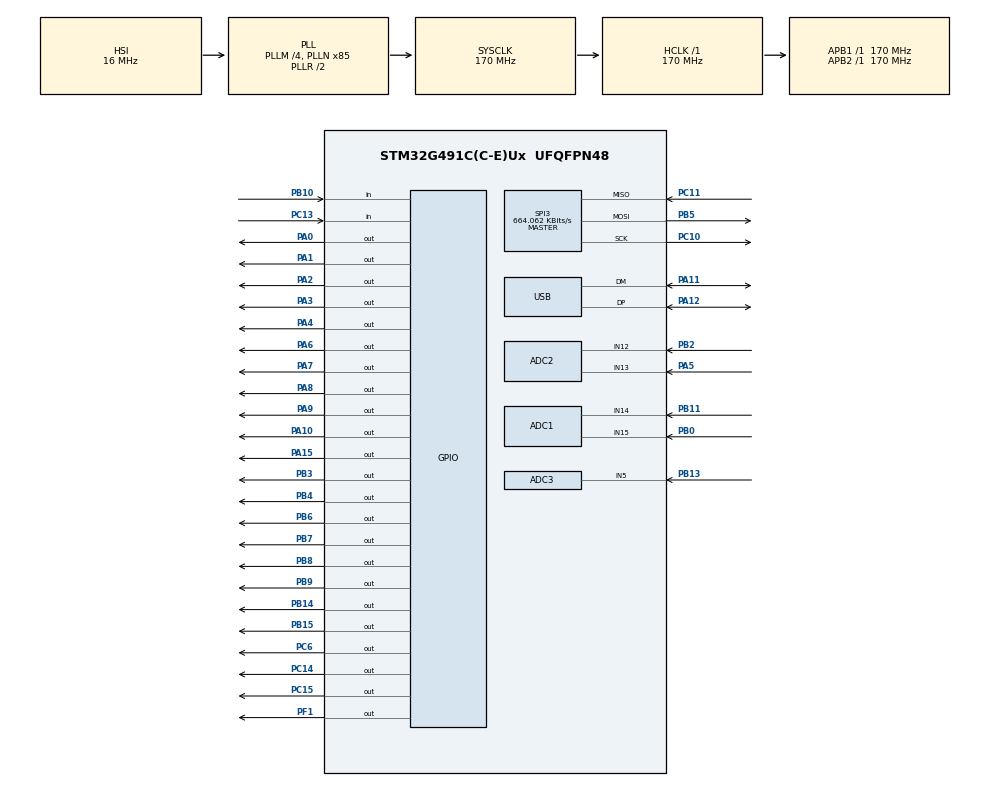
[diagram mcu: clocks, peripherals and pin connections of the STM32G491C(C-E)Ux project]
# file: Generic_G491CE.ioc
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ADC1.Channel-0\#ChannelRegularConversion=ADC_CHANNEL_14
ADC1.NbrOfConversionFlag=1
ADC1.OffsetNumber-0\#ChannelRegularConversion=ADC_OFFSET_NONE
ADC1.Rank-0\#ChannelRegularConversion=1
ADC1.SamplingTime-0\#ChannelRegularConversion=ADC_SAMPLETIME_2CYCLES_5
ADC1.SingleDiff-0\#ChannelRegularConversion=ADC_DIFFERENTIAL_ENDED
ADC1.master=1
ADC2.Channel-0\#ChannelRegularConversion=ADC_CHANNEL_12
ADC2.NbrOfConversionFlag=1
ADC2.OffsetNumber-0\#ChannelRegularConversion=ADC_OFFSET_NONE
ADC2.Rank-0\#ChannelRegularConversion=1
ADC2.SamplingTime-0\#ChannelRegularConversion=ADC_SAMPLETIME_2CYCLES_5
ADC2.SingleDiff-0\#ChannelRegularConversion=ADC_DIFFERENTIAL_ENDED
ADC3.Channel-0\#ChannelRegularConversion=ADC_CHANNEL_5
ADC3.NbrOfConversionFlag=1
ADC3.OffsetNumber-0\#ChannelRegularConversion=ADC_OFFSET_NONE
ADC3.Rank-0\#ChannelRegularConversion=1
ADC3.SamplingTime-0\#ChannelRegularConversion=ADC_SAMPLETIME_2CYCLES_5
ADC3.master=1
FREERTOS.Tasks01=BlinkTask1,24,128,BlinkTask1Function,Default,NULL,Dynamic,NULL,NULL;BlinkTask2,8,128,BlinkTask2Function,Default,NULL,Dynamic,NULL,NULL
FREERTOS.configUSE_NEWLIB_REENTRANT=1
Mcu.Family=STM32G4
Mcu.Name=STM32G491C(C-E)Ux
Mcu.Package=UFQFPN48
NVIC.PriorityGroup=NVIC_PRIORITYGROUP_4
NVIC.TIM6_DAC_IRQn=true\:15\:0\:false\:false\:true\:false\:false\:true\:true
NVIC.TimeBase=TIM6_DAC_IRQn
NVIC.TimeBaseIP=TIM6
NVIC.USB_LP_IRQn=true\:5\:0\:false\:false\:true\:true\:false\:true\:true
PA0.Signal=GPIO_Output
PA1.Signal=GPIO_Output
PA10.Signal=GPIO_Output
PA11.Mode=Device
PA11.Signal=USB_DM
PA12.Mode=Device
PA12.Signal=USB_DP
PA13.Mode=Serial_Wire
PA13.Signal=SYS_JTMS-SWDIO
PA14.Mode=Serial_Wire
PA14.Signal=SYS_JTCK-SWCLK
PA15.Signal=GPIO_Output
PA2.Signal=GPIO_Output
PA3.Signal=GPIO_Output
PA4.Signal=GPIO_Output
PA5.Mode=IN12-Differential
PA5.Signal=ADC2_IN13
PA6.Signal=GPIO_Output
PA7.Signal=GPIO_Output
PA8.Signal=GPIO_Output
PA9.Signal=GPIO_Output
PB0.Mode=IN14-Differential
PB0.Signal=ADC1_IN15
PB1.Signal=ADC1_IN12
PB10.Signal=GPIO_Input
PB11.Mode=IN14-Differential
PB11.Signal=ADC1_IN14
PB12.Signal=ADC1_IN11
PB13.Mode=IN5-Single-Ended
PB13.Signal=ADC3_IN5
PB14.Signal=GPIO_Output
PB15.Signal=GPIO_Output
PB2.Mode=IN12-Differential
PB2.Signal=ADC2_IN12
PB3.Signal=GPIO_Output
PB4.Signal=GPIO_Output
PB5.Mode=Full_Duplex_Master
PB5.Signal=SPI3_MOSI
PB6.Signal=GPIO_Output
PB7.Signal=GPIO_Output
PB8-BOOT0.Signal=GPIO_Output
PB9.Signal=GPIO_Output
PC10.Mode=Full_Duplex_Master
PC10.Signal=SPI3_SCK
PC11.Mode=Full_Duplex_Master
PC11.Signal=SPI3_MISO
PC13.Signal=GPIO_Input
PC14-OSC32_IN.Signal=GPIO_Output
PC15-OSC32_OUT.Signal=GPIO_Output
PC4.Signal=I2C2_SCL
PC6.Signal=GPIO_Output
PF0-OSC_IN.Signal=I2C2_SDA
PF1-OSC_OUT.Signal=GPIO_Output
ProjectManager.HeapSize=0x200
ProjectManager.StackSize=0x400
ProjectManager.TargetToolchain=STM32CubeIDE
RCC.ADC12Freq_Value=170000000
RCC.ADC345Freq_Value=170000000
RCC.AHBFreq_Value=170000000
RCC.APB1Freq_Value=170000000
RCC.APB1TimFreq_Value=170000000
RCC.APB2Freq_Value=170000000
RCC.APB2TimFreq_Value=170000000
RCC.CortexFreq_Value=170000000
RCC.EXTERNAL_CLOCK_VALUE=12288000
RCC.HCLKFreq_Value=170000000
RCC.HSE_VALUE=8000000
RCC.HSI48_VALUE=48000000
RCC.HSI_VALUE=16000000
RCC.LSE_VALUE=32768
RCC.PLLM=RCC_PLLM_DIV4
RCC.PLLN=85
RCC.SYSCLKFreq_VALUE=170000000
RCC.SYSCLKSource=RCC_SYSCLKSOURCE_PLLCLK
RCC.USBFreq_Value=48000000
RCC.VCOOutputFreq_Value=340000000
SPI3.BaudRatePrescaler=SPI_BAUDRATEPRESCALER_256
SPI3.CalculateBaudRate=664.062 KBits/s
SPI3.Direction=SPI_DIRECTION_2LINES
SPI3.Mode=SPI_MODE_MASTER
SPI3.VirtualType=VM_MASTER
USB_DEVICE.CLASS_NAME_FS=DFU
USB_DEVICE.VirtualMode=Dfu
USB_DEVICE.VirtualModeFS=Dfu_FS
VP_CORDIC_VS_CORDIC.Mode=CORDIC_Activate
VP_FMAC_VS_FMAC.Mode=FMAC_Activate
VP_FREERTOS_VS_CMSIS_V2.Mode=CMSIS_V2
VP_RCC_VS_USB.Mode=USB_FS
VP_SYS_VS_DBSignals.Mode=DisableDeadBatterySignals
VP_SYS_VS_tim6.Mode=TIM6
VP_USB_DEVICE_VS_USB_DEVICE_DFU_FS.Mode=DFU_FS
board=custom

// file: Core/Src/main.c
/* USER CODE BEGIN Header */
/**
  ******************************************************************************
  * @file           : main.c
  * @brief          : Main program body
  ******************************************************************************
  * @attention
  *
  * Copyright (c) 2022 STMicroelectronics.
  * All rights reserved.
  *
  * This software is licensed under terms that can be found in the LICENSE file
  * in the root directory of this software component.
  * If no LICENSE file comes with this software, it is provided AS-IS.
  *
  ******************************************************************************
  */
/* USER CODE END Header */
#include "main.h"
#include "cmsis_os.h"
#include "usb_device.h"

ADC_HandleTypeDef hadc1;
ADC_HandleTypeDef hadc2;
ADC_HandleTypeDef hadc3;

CORDIC_HandleTypeDef hcordic;

FMAC_HandleTypeDef hfmac;

SPI_HandleTypeDef hspi3;

/* Definitions for BlinkTask1 */
osThreadId_t BlinkTask1Handle;
const osThreadAttr_t BlinkTask1_attributes = {
  .name = "BlinkTask1",
  .priority = (osPriority_t) osPriorityNormal,
  .stack_size = 128 * 4
};
/* Definitions for BlinkTask2 */
osThreadId_t BlinkTask2Handle;
const osThreadAttr_t BlinkTask2_attributes = {
  .name = "BlinkTask2",
  .priority = (osPriority_t) osPriorityLow,
  .stack_size = 128 * 4
};

void SystemClock_Config(void);
static void MX_GPIO_Init(void);
static void MX_ADC1_Init(void);
static void MX_ADC2_Init(void);
static void MX_ADC3_Init(void);
static void MX_SPI3_Init(void);
static void MX_CORDIC_Init(void);
static void MX_FMAC_Init(void);
void BlinkTask1Function(void *argument);
void BlinkTask2Function(void *argument);

/* USER CODE BEGIN 0 */
//void jump_to_bootloader( void )
//{
//	__enable_irq();
//	HAL_RCC_DeInit();
//	HAL_DeInit();
//	SysTick->CTRL = SysTick->LOAD = SysTick->VAL = 0;
//	__HAL_SYSCFG_REMAPMEMORY_SYSTEMFLASH();
//
//	const uint32_t p = (*((uint32_t *) 0x1FFF0000));
//	__set_MSP( p );
//
//	void (*SysMemBootJump)(void);
//	SysMemBootJump = (void (*)(void)) (*((uint32_t *) 0x1FFF0004));
//	SysMemBootJump();
//
//	while( 1 ) {}
//}

/* USER CODE END 0 */

int main(void)
{
  /* USER CODE BEGIN 1 */

//	// Our STM32 F072 has:
//	// 16k SRAM in address 0x2000 0000 - 0x2000 3FFF
//	*((unsigned long *)0x20003FF0) = 0xDEADBEEF;
//
//	// Reset the processor
//	NVIC_SystemReset();

//	HAL_Delay(1000);

  /* USER CODE END 1 */

  /* MCU Configuration--------------------------------------------------------*/

  /* Reset of all peripherals, Initializes the Flash interface and the Systick. */
  HAL_Init();

  /* Configure the system clock */
  SystemClock_Config();

  /* USER CODE BEGIN SysInit */
//  MODIFY_REG(FLASH->OPTR, FLASH_OPTR_NRST_MODE_Msk, FLASH_OPTR_NRST_MODE_1);
//  MODIFY_REG(FLASH->OPTR, FLASH_OPTR_nBOOT0_Msk, FLASH_OPTR_nBOOT0);
//  MODIFY_REG(FLASH->OPTR, FLASH_OPTR_nSWBOOT0_Msk, OB_BOOT0_FROM_OB);

  /* USER CODE END SysInit */

  /* Initialize all configured peripherals */
  MX_GPIO_Init();
  MX_USB_Device_Init();
  MX_ADC1_Init();
  MX_ADC2_Init();
  MX_ADC3_Init();
  MX_SPI3_Init();
  MX_CORDIC_Init();
  MX_FMAC_Init();

  /* Init scheduler */
  osKernelInitialize();

  /* Create the thread(s) */
  /* creation of BlinkTask1 */
  BlinkTask1Handle = osThreadNew(BlinkTask1Function, NULL, &BlinkTask1_attributes);

  /* creation of BlinkTask2 */
  BlinkTask2Handle = osThreadNew(BlinkTask2Function, NULL, &BlinkTask2_attributes);

  /* Start scheduler */
  osKernelStart();

  /* We should never get here as control is now taken by the scheduler */
  /* Infinite loop */
  /* USER CODE BEGIN WHILE */
  while (1)
  {
//      HAL_GPIO_WritePin(GPIOA, GPIO_PIN_6, GPIO_PIN_SET);
//      vTaskDelay(100);
//      // LED OFF
//      HAL_GPIO_WritePin(GPIOA, GPIO_PIN_6, GPIO_PIN_RESET);
//      vTaskDelay(100);
    /* USER CODE END WHILE */

  }
}

void SystemClock_Config(void)
{
  RCC_OscInitTypeDef RCC_OscInitStruct = {0};
  RCC_ClkInitTypeDef RCC_ClkInitStruct = {0};
  RCC_CRSInitTypeDef pInit = {0};

  /** Configure the main internal regulator output voltage
  */
  HAL_PWREx_ControlVoltageScaling(PWR_REGULATOR_VOLTAGE_SCALE1_BOOST);

  /** Initializes the RCC Oscillators according to the specified parameters
  * in the RCC_OscInitTypeDef structure.
  */
  RCC_OscInitStruct.OscillatorType = RCC_OSCILLATORTYPE_HSI|RCC_OSCILLATORTYPE_HSI48;
  RCC_OscInitStruct.HSIState = RCC_HSI_ON;
  RCC_OscInitStruct.HSICalibrationValue = RCC_HSICALIBRATION_DEFAULT;
  RCC_OscInitStruct.HSI48State = RCC_HSI48_ON;
  RCC_OscInitStruct.PLL.PLLState = RCC_PLL_ON;
  RCC_OscInitStruct.PLL.PLLSource = RCC_PLLSOURCE_HSI;
  RCC_OscInitStruct.PLL.PLLM = RCC_PLLM_DIV4;
  RCC_OscInitStruct.PLL.PLLN = 85;
  RCC_OscInitStruct.PLL.PLLP = RCC_PLLP_DIV2;
  RCC_OscInitStruct.PLL.PLLQ = RCC_PLLQ_DIV2;
  RCC_OscInitStruct.PLL.PLLR = RCC_PLLR_DIV2;
  if (HAL_RCC_OscConfig(&RCC_OscInitStruct) != HAL_OK)
  {
    Error_Handler();
  }

  /** Initializes the CPU, AHB and APB buses clocks
  */
  RCC_ClkInitStruct.ClockType = RCC_CLOCKTYPE_HCLK|RCC_CLOCKTYPE_SYSCLK
                              |RCC_CLOCKTYPE_PCLK1|RCC_CLOCKTYPE_PCLK2;
  RCC_ClkInitStruct.SYSCLKSource = RCC_SYSCLKSOURCE_PLLCLK;
  RCC_ClkInitStruct.AHBCLKDivider = RCC_SYSCLK_DIV1;
  RCC_ClkInitStruct.APB1CLKDivider = RCC_HCLK_DIV1;
  RCC_ClkInitStruct.APB2CLKDivider = RCC_HCLK_DIV1;

  if (HAL_RCC_ClockConfig(&RCC_ClkInitStruct, FLASH_LATENCY_4) != HAL_OK)
  {
    Error_Handler();
  }

  /** Enable the SYSCFG APB clock
  */
  __HAL_RCC_CRS_CLK_ENABLE();

  /** Configures CRS
  */
  pInit.Prescaler = RCC_CRS_SYNC_DIV1;
  pInit.Source = RCC_CRS_SYNC_SOURCE_USB;
  pInit.Polarity = RCC_CRS_SYNC_POLARITY_RISING;
  pInit.ReloadValue = __HAL_RCC_CRS_RELOADVALUE_CALCULATE(48000000,1000);
  pInit.ErrorLimitValue = 34;
  pInit.HSI48CalibrationValue = 32;

  HAL_RCCEx_CRSConfig(&pInit);
}

static void MX_ADC1_Init(void)
{

  ADC_MultiModeTypeDef multimode = {0};
  ADC_ChannelConfTypeDef sConfig = {0};

  /** Common config
  */
  hadc1.Instance = ADC1;
  hadc1.Init.ClockPrescaler = ADC_CLOCK_SYNC_PCLK_DIV4;
  hadc1.Init.Resolution = ADC_RESOLUTION_12B;
  hadc1.Init.DataAlign = ADC_DATAALIGN_RIGHT;
  hadc1.Init.GainCompensation = 0;
  hadc1.Init.ScanConvMode = ADC_SCAN_DISABLE;
  hadc1.Init.EOCSelection = ADC_EOC_SINGLE_CONV;
  hadc1.Init.LowPowerAutoWait = DISABLE;
  hadc1.Init.ContinuousConvMode = DISABLE;
  hadc1.Init.NbrOfConversion = 1;
  hadc1.Init.DiscontinuousConvMode = DISABLE;
  hadc1.Init.ExternalTrigConv = ADC_SOFTWARE_START;
  hadc1.Init.ExternalTrigConvEdge = ADC_EXTERNALTRIGCONVEDGE_NONE;
  hadc1.Init.DMAContinuousRequests = DISABLE;
  hadc1.Init.Overrun = ADC_OVR_DATA_PRESERVED;
  hadc1.Init.OversamplingMode = DISABLE;
  if (HAL_ADC_Init(&hadc1) != HAL_OK)
  {
    Error_Handler();
  }

  /** Configure the ADC multi-mode
  */
  multimode.Mode = ADC_MODE_INDEPENDENT;
  if (HAL_ADCEx_MultiModeConfigChannel(&hadc1, &multimode) != HAL_OK)
  {
    Error_Handler();
  }

  /** Configure Regular Channel
  */
  sConfig.Channel = ADC_CHANNEL_14;
  sConfig.Rank = ADC_REGULAR_RANK_1;
  sConfig.SamplingTime = ADC_SAMPLETIME_2CYCLES_5;
  sConfig.SingleDiff = ADC_DIFFERENTIAL_ENDED;
  sConfig.OffsetNumber = ADC_OFFSET_NONE;
  sConfig.Offset = 0;
  if (HAL_ADC_ConfigChannel(&hadc1, &sConfig) != HAL_OK)
  {
    Error_Handler();
  }

}

static void MX_ADC2_Init(void)
{

  ADC_ChannelConfTypeDef sConfig = {0};

  /** Common config
  */
  hadc2.Instance = ADC2;
  hadc2.Init.ClockPrescaler = ADC_CLOCK_SYNC_PCLK_DIV4;
  hadc2.Init.Resolution = ADC_RESOLUTION_12B;
  hadc2.Init.DataAlign = ADC_DATAALIGN_RIGHT;
  hadc2.Init.GainCompensation = 0;
  hadc2.Init.ScanConvMode = ADC_SCAN_DISABLE;
  hadc2.Init.EOCSelection = ADC_EOC_SINGLE_CONV;
  hadc2.Init.LowPowerAutoWait = DISABLE;
  hadc2.Init.ContinuousConvMode = DISABLE;
  hadc2.Init.NbrOfConversion = 1;
  hadc2.Init.DiscontinuousConvMode = DISABLE;
  hadc2.Init.ExternalTrigConv = ADC_SOFTWARE_START;
  hadc2.Init.ExternalTrigConvEdge = ADC_EXTERNALTRIGCONVEDGE_NONE;
  hadc2.Init.DMAContinuousRequests = DISABLE;
  hadc2.Init.Overrun = ADC_OVR_DATA_PRESERVED;
  hadc2.Init.OversamplingMode = DISABLE;
  if (HAL_ADC_Init(&hadc2) != HAL_OK)
  {
    Error_Handler();
  }

  /** Configure Regular Channel
  */
  sConfig.Channel = ADC_CHANNEL_12;
  sConfig.Rank = ADC_REGULAR_RANK_1;
  sConfig.SamplingTime = ADC_SAMPLETIME_2CYCLES_5;
  sConfig.SingleDiff = ADC_DIFFERENTIAL_ENDED;
  sConfig.OffsetNumber = ADC_OFFSET_NONE;
  sConfig.Offset = 0;
  if (HAL_ADC_ConfigChannel(&hadc2, &sConfig) != HAL_OK)
  {
    Error_Handler();
  }

}

static void MX_ADC3_Init(void)
{

  ADC_ChannelConfTypeDef sConfig = {0};

  /** Common config
  */
  hadc3.Instance = ADC3;
  hadc3.Init.ClockPrescaler = ADC_CLOCK_SYNC_PCLK_DIV4;
  hadc3.Init.Resolution = ADC_RESOLUTION_12B;
  hadc3.Init.DataAlign = ADC_DATAALIGN_RIGHT;
  hadc3.Init.GainCompensation = 0;
  hadc3.Init.ScanConvMode = ADC_SCAN_DISABLE;
  hadc3.Init.EOCSelection = ADC_EOC_SINGLE_CONV;
  hadc3.Init.LowPowerAutoWait = DISABLE;
  hadc3.Init.ContinuousConvMode = DISABLE;
  hadc3.Init.NbrOfConversion = 1;
  hadc3.Init.DiscontinuousConvMode = DISABLE;
  hadc3.Init.ExternalTrigConv = ADC_SOFTWARE_START;
  hadc3.Init.ExternalTrigConvEdge = ADC_EXTERNALTRIGCONVEDGE_NONE;
  hadc3.Init.DMAContinuousRequests = DISABLE;
  hadc3.Init.Overrun = ADC_OVR_DATA_PRESERVED;
  hadc3.Init.OversamplingMode = DISABLE;
  if (HAL_ADC_Init(&hadc3) != HAL_OK)
  {
    Error_Handler();
  }

  /** Configure Regular Channel
  */
  sConfig.Channel = ADC_CHANNEL_5;
  sConfig.Rank = ADC_REGULAR_RANK_1;
  sConfig.SamplingTime = ADC_SAMPLETIME_2CYCLES_5;
  sConfig.SingleDiff = ADC_SINGLE_ENDED;
  sConfig.OffsetNumber = ADC_OFFSET_NONE;
  sConfig.Offset = 0;
  if (HAL_ADC_ConfigChannel(&hadc3, &sConfig) != HAL_OK)
  {
    Error_Handler();
  }

}

static void MX_CORDIC_Init(void)
{

  hcordic.Instance = CORDIC;
  if (HAL_CORDIC_Init(&hcordic) != HAL_OK)
  {
    Error_Handler();
  }

}

static void MX_FMAC_Init(void)
{

  hfmac.Instance = FMAC;
  if (HAL_FMAC_Init(&hfmac) != HAL_OK)
  {
    Error_Handler();
  }

}

static void MX_SPI3_Init(void)
{

  /* SPI3 parameter configuration*/
  hspi3.Instance = SPI3;
  hspi3.Init.Mode = SPI_MODE_MASTER;
  hspi3.Init.Direction = SPI_DIRECTION_2LINES;
  hspi3.Init.DataSize = SPI_DATASIZE_8BIT;
  hspi3.Init.CLKPolarity = SPI_POLARITY_LOW;
  hspi3.Init.CLKPhase = SPI_PHASE_1EDGE;
  hspi3.Init.NSS = SPI_NSS_SOFT;
  hspi3.Init.BaudRatePrescaler = SPI_BAUDRATEPRESCALER_256;
  hspi3.Init.FirstBit = SPI_FIRSTBIT_MSB;
  hspi3.Init.TIMode = SPI_TIMODE_DISABLE;
  hspi3.Init.CRCCalculation = SPI_CRCCALCULATION_DISABLE;
  hspi3.Init.CRCPolynomial = 7;
  hspi3.Init.CRCLength = SPI_CRC_LENGTH_DATASIZE;
  hspi3.Init.NSSPMode = SPI_NSS_PULSE_ENABLE;
  if (HAL_SPI_Init(&hspi3) != HAL_OK)
  {
    Error_Handler();
  }

}

static void MX_GPIO_Init(void)
{
  GPIO_InitTypeDef GPIO_InitStruct = {0};

  /* GPIO Ports Clock Enable */
  __HAL_RCC_GPIOC_CLK_ENABLE();
  __HAL_RCC_GPIOF_CLK_ENABLE();
  __HAL_RCC_GPIOA_CLK_ENABLE();
  __HAL_RCC_GPIOB_CLK_ENABLE();

  /*Configure GPIO pin Output Level */
  HAL_GPIO_WritePin(GPIOC, GPIO_PIN_14|GPIO_PIN_15|GPIO_PIN_6, GPIO_PIN_RESET);

  /*Configure GPIO pin Output Level */
  HAL_GPIO_WritePin(GPIOF, GPIO_PIN_1, GPIO_PIN_RESET);

  /*Configure GPIO pin Output Level */
  HAL_GPIO_WritePin(GPIOA, GPIO_PIN_0|GPIO_PIN_1|GPIO_PIN_2|GPIO_PIN_3
                          |GPIO_PIN_4|GPIO_PIN_6|GPIO_PIN_7|GPIO_PIN_8
                          |GPIO_PIN_9|GPIO_PIN_10|GPIO_PIN_15, GPIO_PIN_RESET);

  /*Configure GPIO pin Output Level */
  HAL_GPIO_WritePin(GPIOB, GPIO_PIN_14|GPIO_PIN_15|GPIO_PIN_3|GPIO_PIN_4
                          |GPIO_PIN_6|GPIO_PIN_7|GPIO_PIN_8|GPIO_PIN_9, GPIO_PIN_RESET);

  /*Configure GPIO pin : PC13 */
  GPIO_InitStruct.Pin = GPIO_PIN_13;
  GPIO_InitStruct.Mode = GPIO_MODE_INPUT;
  GPIO_InitStruct.Pull = GPIO_NOPULL;
  HAL_GPIO_Init(GPIOC, &GPIO_InitStruct);

  /*Configure GPIO pins : PC14 PC15 PC6 */
  GPIO_InitStruct.Pin = GPIO_PIN_14|GPIO_PIN_15|GPIO_PIN_6;
  GPIO_InitStruct.Mode = GPIO_MODE_OUTPUT_PP;
  GPIO_InitStruct.Pull = GPIO_NOPULL;
  GPIO_InitStruct.Speed = GPIO_SPEED_FREQ_LOW;
  HAL_GPIO_Init(GPIOC, &GPIO_InitStruct);

  /*Configure GPIO pin : PF0 */
  GPIO_InitStruct.Pin = GPIO_PIN_0;
  GPIO_InitStruct.Mode = GPIO_MODE_AF_OD;
  GPIO_InitStruct.Pull = GPIO_NOPULL;
  GPIO_InitStruct.Speed = GPIO_SPEED_FREQ_LOW;
  GPIO_InitStruct.Alternate = GPIO_AF4_I2C2;
  HAL_GPIO_Init(GPIOF, &GPIO_InitStruct);

  /*Configure GPIO pin : PF1 */
  GPIO_InitStruct.Pin = GPIO_PIN_1;
  GPIO_InitStruct.Mode = GPIO_MODE_OUTPUT_PP;
  GPIO_InitStruct.Pull = GPIO_NOPULL;
  GPIO_InitStruct.Speed = GPIO_SPEED_FREQ_LOW;
  HAL_GPIO_Init(GPIOF, &GPIO_InitStruct);

  /*Configure GPIO pins : PA0 PA1 PA2 PA3
                           PA4 PA6 PA7 PA8
                           PA9 PA10 PA15 */
  GPIO_InitStruct.Pin = GPIO_PIN_0|GPIO_PIN_1|GPIO_PIN_2|GPIO_PIN_3
                          |GPIO_PIN_4|GPIO_PIN_6|GPIO_PIN_7|GPIO_PIN_8
                          |GPIO_PIN_9|GPIO_PIN_10|GPIO_PIN_15;
  GPIO_InitStruct.Mode = GPIO_MODE_OUTPUT_PP;
  GPIO_InitStruct.Pull = GPIO_NOPULL;
  GPIO_InitStruct.Speed = GPIO_SPEED_FREQ_LOW;
  HAL_GPIO_Init(GPIOA, &GPIO_InitStruct);

  /*Configure GPIO pin : PC4 */
  GPIO_InitStruct.Pin = GPIO_PIN_4;
  GPIO_InitStruct.Mode = GPIO_MODE_AF_OD;
  GPIO_InitStruct.Pull = GPIO_NOPULL;
  GPIO_InitStruct.Speed = GPIO_SPEED_FREQ_LOW;
  GPIO_InitStruct.Alternate = GPIO_AF4_I2C2;
  HAL_GPIO_Init(GPIOC, &GPIO_InitStruct);

  /*Configure GPIO pin : PB10 */
  GPIO_InitStruct.Pin = GPIO_PIN_10;
  GPIO_InitStruct.Mode = GPIO_MODE_INPUT;
  GPIO_InitStruct.Pull = GPIO_NOPULL;
  HAL_GPIO_Init(GPIOB, &GPIO_InitStruct);

  /*Configure GPIO pins : PB14 PB15 PB3 PB4
                           PB6 PB7 PB8 PB9 */
  GPIO_InitStruct.Pin = GPIO_PIN_14|GPIO_PIN_15|GPIO_PIN_3|GPIO_PIN_4
                          |GPIO_PIN_6|GPIO_PIN_7|GPIO_PIN_8|GPIO_PIN_9;
  GPIO_InitStruct.Mode = GPIO_MODE_OUTPUT_PP;
  GPIO_InitStruct.Pull = GPIO_NOPULL;
  GPIO_InitStruct.Speed = GPIO_SPEED_FREQ_LOW;
  HAL_GPIO_Init(GPIOB, &GPIO_InitStruct);

}

void BlinkTask1Function(void *argument)
{
  /* USER CODE BEGIN 5 */
  /* Infinite loop */
  for(;;)
  {
      HAL_GPIO_WritePin(GPIOA, GPIO_PIN_7, GPIO_PIN_SET);
      vTaskDelay(100);
      // LED OFF
      HAL_GPIO_WritePin(GPIOA, GPIO_PIN_7, GPIO_PIN_RESET);
      vTaskDelay(100);
//    osDelay(1);
  }
  /* USER CODE END 5 */
}

void BlinkTask2Function(void *argument)
{
  /* USER CODE BEGIN BlinkTask2Function */
  /* Infinite loop */
  for(;;)
  {
      HAL_GPIO_WritePin(GPIOA, GPIO_PIN_6, GPIO_PIN_SET);
      vTaskDelay(100);
      // LED OFF
      HAL_GPIO_WritePin(GPIOA, GPIO_PIN_6, GPIO_PIN_RESET);
      vTaskDelay(100);
//    osDelay(1);
  }
  /* USER CODE END BlinkTask2Function */
}

void HAL_TIM_PeriodElapsedCallback(TIM_HandleTypeDef *htim)
{
  if (htim->Instance == TIM6) {
    HAL_IncTick();
  }
}

void Error_Handler(void)
{
  __disable_irq();
  while (1)
  {
  }
}
